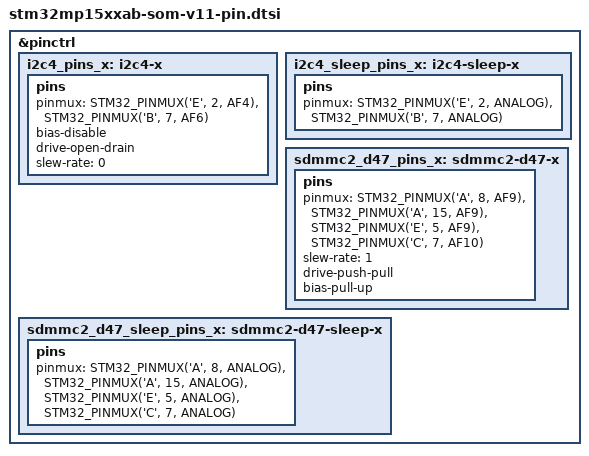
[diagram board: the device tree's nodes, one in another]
// SPDX-License-Identifier: (GPL-2.0+ OR BSD-3-Clause)
/*
 * Copyright (C) OneKiwi 2024 - All Rights Reserved
 * Author: Thanh Duong <thanh.duong.vs@gmail.com> for OneKiwi.
 */
#include <dt-bindings/pinctrl/stm32-pinfunc.h>

&pinctrl {
	i2c4_pins_x: i2c4-x {
		pins {
			pinmux = <STM32_PINMUX('E', 2, AF4)>, /* I2C4_SCL */
				 <STM32_PINMUX('B', 7, AF6)>; /* I2C4_SDA */
			bias-disable;
			drive-open-drain;
			slew-rate = <0>;
		};
	};

	i2c4_sleep_pins_x: i2c4-sleep-x {
		pins {
			pinmux = <STM32_PINMUX('E', 2, ANALOG)>, /* I2C4_SCL */
				 <STM32_PINMUX('B', 7, ANALOG)>; /* I2C4_SDA */
		};
	};
	
	sdmmc2_d47_pins_x: sdmmc2-d47-x {
		pins {
			pinmux = <STM32_PINMUX('A', 8, AF9)>, /* SDMMC2_D4 */
				 <STM32_PINMUX('A', 15, AF9)>, /* SDMMC2_D5 */
				 <STM32_PINMUX('E', 5, AF9)>, /* SDMMC2_D6 */
				 <STM32_PINMUX('C', 7, AF10)>; /* SDMMC2_D7 */
			slew-rate = <1>;
			drive-push-pull;
			bias-pull-up;
		};
	};

	sdmmc2_d47_sleep_pins_x: sdmmc2-d47-sleep-x {
		pins {
			pinmux = <STM32_PINMUX('A', 8, ANALOG)>, /* SDMMC2_D4 */
				 <STM32_PINMUX('A', 15, ANALOG)>, /* SDMMC2_D5 */
				 <STM32_PINMUX('E', 5, ANALOG)>, /* SDMMC2_D6 */
				 <STM32_PINMUX('C', 7, ANALOG)>; /* SDMMC2_D7 */
		};
	};
};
